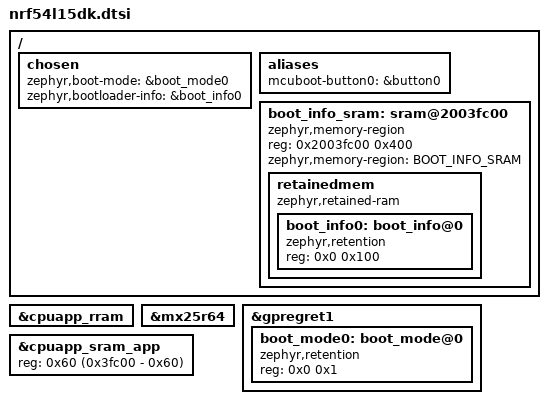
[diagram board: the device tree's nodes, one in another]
/* Delete Zephyr-default partitions before redefining them. */
&cpuapp_rram { /delete-node/ partitions; };

&mx25r64 {
	status = "okay";
};

&gpregret1 {
	status = "okay";

	boot_mode0: boot_mode@0 {
		compatible = "zephyr,retention";
		status = "okay";
		reg = <0x0 0x1>;
	};
};

/ {
	chosen {
		zephyr,boot-mode = &boot_mode0;
	};

	aliases {
		mcuboot-button0 = &button0;
	};
};

#include "nrf54l15dk-partitions.dtsi"

/* Bootloader info shared-data area: the last KB of this board's RAM, kept
 * out of the managed RAM so neither image clobbers it. The bootloader
 * writes its boot state here on every boot (BOOT_SHARE_DATA_BOOTINFO ->
 * BLINFO TLVs via boot_write_shared_data()); the application reads the
 * same region to answer the SMP bootloader-info command (RETENTION_
 * BOOTLOADER_INFO_TYPE_MCUBOOT). Carved here because this dtsi applies to
 * both images.
 *
 * zephyr,sram is cpuapp_sram_app, which Zephyr requires to stay inside
 * cpuapp_sram, so shorten cpuapp_sram_app rather than cpuapp_sram. Its reg
 * is relative to cpuapp_sram and starts at 0x60. */
&cpuapp_sram_app {
	reg = <0x60 (0x3fc00 - 0x60)>;
};

/ {
	chosen {
		zephyr,bootloader-info = &boot_info0;
	};

	boot_info_sram: sram@2003fc00 {
		compatible = "zephyr,memory-region", "mmio-sram";
		reg = <0x2003fc00 0x400>;
		zephyr,memory-region = "BOOT_INFO_SRAM";
		status = "okay";

		retainedmem {
			compatible = "zephyr,retained-ram";
			status = "okay";
			#address-cells = <1>;
			#size-cells = <1>;

			boot_info0: boot_info@0 {
				compatible = "zephyr,retention";
				status = "okay";
				reg = <0x0 0x100>;
			};
		};
	};
};
